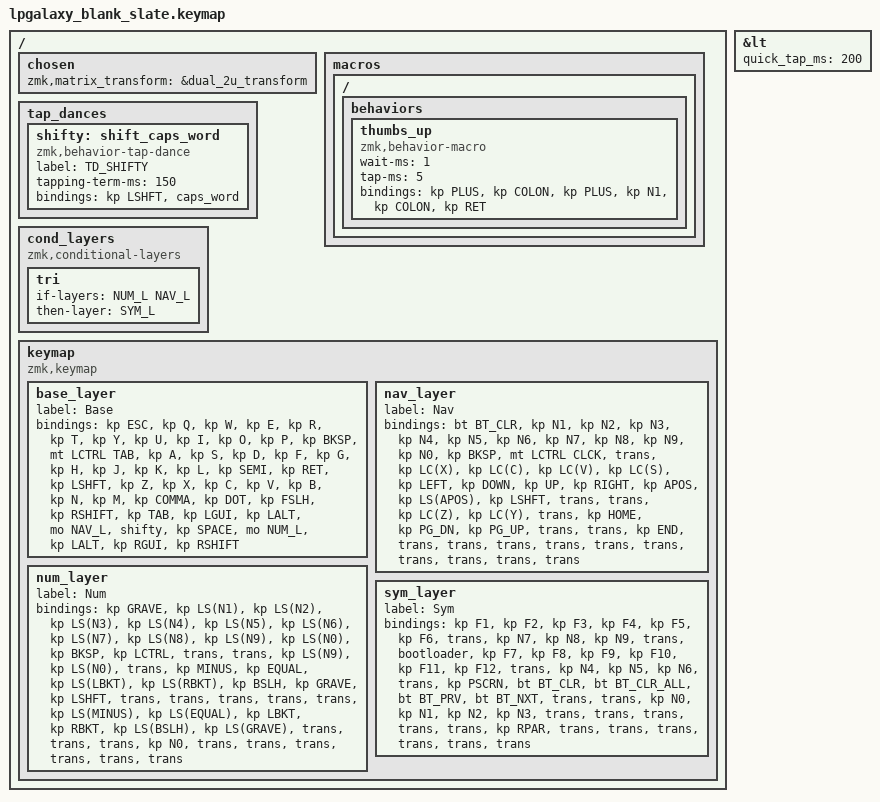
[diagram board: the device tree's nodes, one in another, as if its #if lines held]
/*
 * Copyright (c) 2022 Pete Johanson
 *
 * SPDX-License-Identifier: MIT
 */

#include <behaviors.dtsi>
#include <dt-bindings/zmk/keys.h>
#include <dt-bindings/zmk/bt.h>
#include <dt-bindings/zmk/outputs.h>

#define QWERTY_BASE 1

#define TBLE_ORTHO   1
#define TBLE_MIT     1
// #define TBLE_DUAL_2U 1

#define NAV_L 1
#define NUM_L 2
#define SYM_L 3

// Using layer taps on thumbs, having quick tap as well helps w/ repeating space/backspace 
&lt { quick_tap_ms = <200>; };

#define BT(n) BT_SEL n

/ {
    chosen {
       zmk,matrix_transform =
#ifdef TBLE_DUAL_2U
                       &dual_2u_transform;
#elif defined(TBLE_MIT)
                       &mit_transform;
#else
                       &ortho_transform;
#endif
    };

    macros {
      ZMK_MACRO(thumbs_up,
		wait-ms = <1>;
		tap-ms = <5>;
                bindings = <&kp PLUS &kp COLON &kp PLUS &kp N1 &kp COLON &kp RET>;
		)
    };
    
    tap_dances {
    	shifty: shift_caps_word {
		compatible = "zmk,behavior-tap-dance";
		label = "TD_SHIFTY";
		#binding-cells = <0>;
		tapping-term-ms = <150>;
		bindings = <&kp LSHFT>, <&caps_word>;
	};
    };

// Conditional layer only when we have less thumb keys
#ifdef TBLE_DUAL_2U
    cond_layers {
        compatible = "zmk,conditional-layers";
	tri {
	    if-layers = <NUM_L NAV_L>;
	    then-layer = <SYM_L>;
        };
    };
#endif

#ifdef TBLE_MIT
    cond_layers {
        compatible = "zmk,conditional-layers";
	tri {
	    if-layers = <NUM_L NAV_L>;
	    then-layer = <SYM_L>;
        };
    };
#endif

    keymap {
        compatible = "zmk,keymap";

        base_layer {
            label = "Base";
            bindings = <
#ifdef QWERTY_BASE
 &kp ESC    &kp Q      &kp W      &kp E       &kp R          &kp T          &kp Y            &kp U          &kp I       &kp O      &kp P         &kp BKSP
 &mt LCTRL TAB &kp A   &kp S      &kp D       &kp F          &kp G          &kp H            &kp J          &kp K       &kp L      &kp SEMI      &kp RET
 &kp LSHFT  &kp Z      &kp X      &kp C       &kp V          &kp B          &kp N            &kp M          &kp COMMA   &kp DOT    &kp FSLH      &kp RSHIFT
#else
 &kp ESC    &kp Q      &kp W      &kp F       &kp P          &kp B          &kp J            &kp L          &kp U       &kp Y      &kp QUOT      &kp BKSP
 &kp LCTRL  &kp A      &kp R      &kp S       &kp T          &kp G          &kp M            &kp N          &kp E       &kp I      &kp O         &kp RET
 &kp LSHFT  &kp Z      &kp X      &kp C       &kp D          &kp V          &kp K            &kp H          &kp COMMA   &kp DOT    &kp SEMI      &kp RSHIFT
#endif
#ifdef TBLE_DUAL_2U
 &kp TAB  &kp LGUI   &kp LALT   &mo NAV_L         &shifty                        &kp SPACE                &mo NUM_L   &kp LALT   &kp RGUI      &kp RSHIFT
#elif defined(TBLE_MIT)
 &kp LALT  &mo CLCK   &kp TAB  &kp LGUI    &mo NAV_L          &kp SPACE                   &mo NUM_L      &kp RET    &kp DEL     &kp LEFT      &kp RIGHT
#else
 &kp LALT   &kp CLCK    &kp TAB  &kp LGUI    &mo NAV_L      &kp SPACE      &kp RET          &mo NUM_L      &kp LEFT    &kp DEL     &kp LEFT      &kp RIGHT
#endif
            >;
        };

        nav_layer {
            label = "Nav";
            bindings = <
&bt BT_CLR &kp N1     &kp N2     &kp N3      &kp N4          &kp N5       &kp N6     &kp N7         &kp N8      &kp N9     &kp N0     &kp BKSP
&mt LCTRL CLCK &trans &kp LC(X) &kp LC(C)   &kp LC(V)       &kp LC(S)    &kp LEFT   &kp DOWN       &kp UP      &kp RIGHT  &kp APOS   &kp LS(APOS)
&kp LSHFT      &trans &trans    &kp LC(Z)   &kp LC(Y)          &trans    &kp HOME   &kp PG_DN      &kp PG_UP      &trans     &trans     &kp END
#ifdef TBLE_DUAL_2U
&trans  &trans        &trans     &trans              &trans                    &trans       &trans         &trans &trans &trans
#elif defined(TBLE_MIT)
&kp LALT  &trans   &kp TAB  &kp LGUI    &mo NAV_L          &kp SPACE                   &mo NUM_L      &bt BT(1)  &bt BT(2)   &bt BT(3)       &bt BT(4)
#else
&trans  &trans        &trans     &trans      &trans          &trans       &trans    &trans  &trans         &trans &trans &trans
#endif
            >;
        };

        num_layer {
            label = "Num";
            bindings = <
&kp GRAVE  &kp LS(N1) &kp LS(N2) &kp LS(N3) &kp LS(N4)  &kp LS(N5) &kp LS(N6)  &kp LS(N7)      &kp LS(N8)    &kp LS(N9)   &kp LS(N0)   &kp BKSP
&kp LCTRL  &trans    &trans    &kp LS(N9) &kp LS(N0)  &trans    &kp MINUS     &kp EQUAL     &kp LS(LBKT)  &kp LS(RBKT) &kp BSLH     &kp GRAVE
&kp LSHFT  &trans    &trans    &trans    &trans     &trans    &kp LS(MINUS) &kp LS(EQUAL) &kp LBKT      &kp RBKT     &kp LS(BSLH) &kp LS(GRAVE)
#ifdef TBLE_DUAL_2U
&trans  &trans       &trans     &kp N0              &trans                 &trans            &trans         &trans &trans &trans
#elif defined(TBLE_MIT)
&trans  &trans       &trans     &kp N0      &trans           &none            &trans        &kp DEL      &trans &trans &trans
#else
&trans  &trans       &trans     &kp N0      &trans    &none         &none     &kp ESC        &kp DEL      &trans &trans &trans
#endif
            >;
        };

        sym_layer {
            label = "Sym";
            bindings = <
&kp F1     &kp F2     &kp F3     &kp F4      &kp F5       &kp F6       &trans     &kp N7    &kp N8       &kp N9       &trans     &bootloader
&kp F7     &kp F8     &kp F9     &kp F10     &kp F11      &kp F12      &trans     &kp N4    &kp N5       &kp N6       &trans     &kp PSCRN
&bt BT_CLR &bt BT_CLR_ALL &bt BT_PRV &bt BT_NXT &trans       &trans     &kp N0     &kp N1    &kp N2       &kp N3       &trans     &trans
#ifdef TBLE_DUAL_2U
&trans &trans        &trans     &kp RPAR                &trans                    &trans       &trans         &trans &trans &trans
#elif defined(TBLE_MIT)
&trans &trans        &trans     &kp RPAR        &trans                &trans             &trans  &bt BT_SEL 0   &bt BT_SEL 1 &bt BT_SEL 2 &bt BT_SEL 3
#else
&trans &trans        &trans     &kp RPAR        &trans          &trans       &trans    &trans  &trans         &trans &trans &trans
#endif
            >;
        };


    };
};

